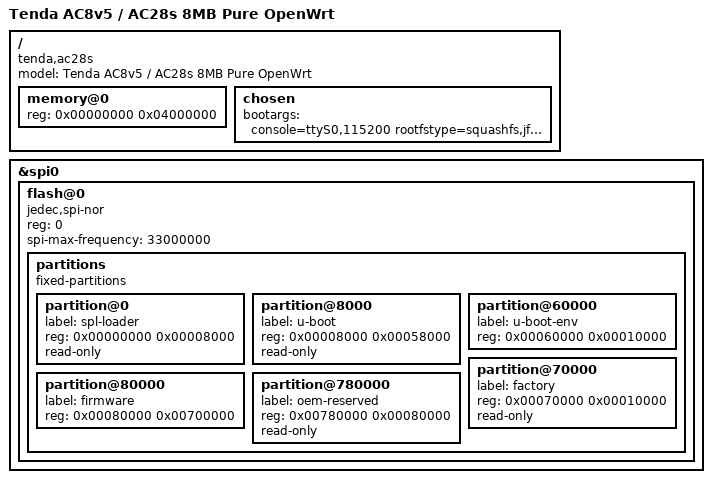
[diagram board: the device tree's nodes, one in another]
/dts-v1/;
#include "sf19a28_fullmask.dtsi"

/ {
	model = "Tenda AC8v5 / AC28s 8MB Pure OpenWrt";
	compatible = "tenda,ac28s", "sf,sfa28", "sf,sf19a28";

	memory@0 {
		device_type = "memory";
		reg = <0x00000000 0x04000000>; /* 64 MB DDR2 */
	};

	chosen {
		bootargs = "console=ttyS0,115200 rootfstype=squashfs,jffs2";
	};
};

&spi0 {
	status = "okay";
	flash@0 {
		compatible = "jedec,spi-nor";
		reg = <0>;
		spi-max-frequency = <33000000>;

		partitions {
			compatible = "fixed-partitions";
			#address-cells = <1>;
			#size-cells = <1>;

			/* 1. SPL Bootloader (sa18 magic) */
			partition@0 {
				label = "spl-loader";
				reg = <0x00000000 0x00008000>;
				read-only;
			};

			/* 2. U-Boot 2016.07 */
			partition@8000 {
				label = "u-boot";
				reg = <0x00008000 0x00058000>;
				read-only;
			};

			/* 3. U-Boot Environment Variables */
			partition@60000 {
				label = "u-boot-env";
				reg = <0x00060000 0x00010000>;
			};

			/* 4. Factory EEPROM (RF Caldata & Asli MAC) */
			partition@70000 {
				label = "factory";
				reg = <0x00070000 0x00010000>;
				read-only;
			};

			/* 5. Pure OpenWrt Firmware (Kernel + SquashFS RootFS) */
			partition@80000 {
				label = "firmware";
				reg = <0x00080000 0x00700000>;
			};

			/* 6. OEM Reserved / CFM Config */
			partition@780000 {
				label = "oem-reserved";
				reg = <0x00780000 0x00080000>;
				read-only;
			};
		};
	};
};
